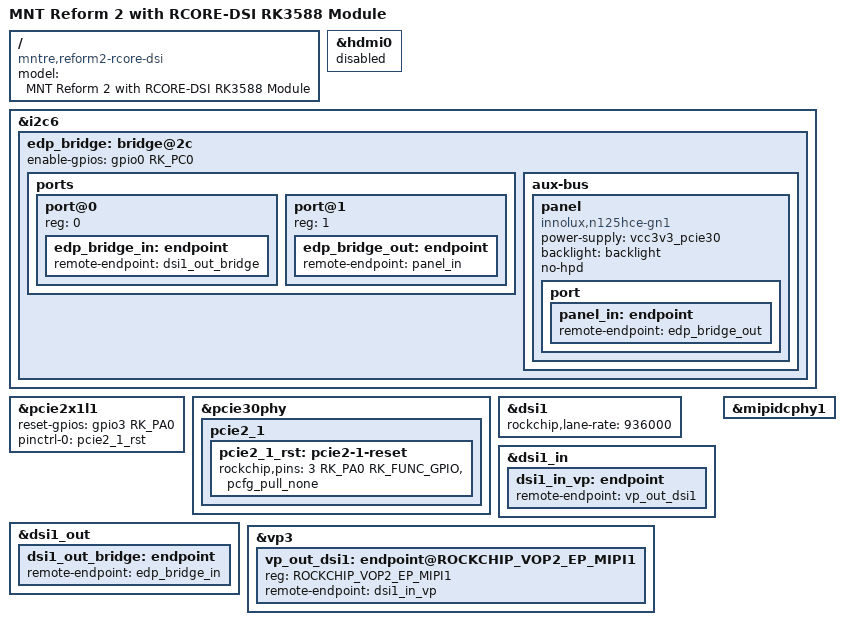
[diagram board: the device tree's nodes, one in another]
// SPDX-License-Identifier: (GPL-2.0+ OR MIT)
/*
 * Copyright (c) 2021 Rockchip Electronics Co., Ltd.
 * Copyright (c) 2024 MNT Research GmbH
 *
 */

/dts-v1/;

#include "rk3588-mnt-reform2.dts"

/ {
	model = "MNT Reform 2 with RCORE-DSI RK3588 Module";
	compatible = "mntre,reform2-rcore-dsi", "firefly,icore-3588q", "rockchip,rk3588";
};

&hdmi0 {
	status = "disabled";
};

&i2c6 {
	edp_bridge: bridge@2c {
		enable-gpios = <&gpio0 RK_PC0 GPIO_ACTIVE_HIGH>;
		status = "okay";

		ports {
			#address-cells = <1>;
			#size-cells = <0>;

			port@0 {
				reg = <0>;

				edp_bridge_in: endpoint {
					remote-endpoint = <&dsi1_out_bridge>;
				};
			};

			port@1 {
				reg = <1>;

				edp_bridge_out: endpoint {
					remote-endpoint = <&panel_in>;
				};
			};
		};

		aux-bus {
			panel: panel {
				compatible = "innolux,n125hce-gn1";
				power-supply = <&vcc3v3_pcie30>;
				backlight = <&backlight>;
				no-hpd;

				port {
					panel_in: endpoint {
						remote-endpoint = <&edp_bridge_out>;
					};
				};
			};
		};
	};
};

/* only for wifi/bt connector on RCORE R-2 */
&pcie2x1l1 {
	reset-gpios = <&gpio3 RK_PA0 GPIO_ACTIVE_HIGH>;
	pinctrl-names = "default";
	pinctrl-0 = <&pcie2_1_rst>;
	status = "okay";
};

&pcie30phy {
	pcie2_1 {
		pcie2_1_rst: pcie2-1-reset {
			rockchip,pins = <3 RK_PA0 RK_FUNC_GPIO &pcfg_pull_none>;
		};
	};
};

&dsi1 {
	rockchip,lane-rate = <936000>;
	status = "okay";
};

&dsi1_in {
	dsi1_in_vp: endpoint {
		remote-endpoint = <&vp_out_dsi1>;
	};
};

&dsi1_out {
	dsi1_out_bridge: endpoint {
		remote-endpoint = <&edp_bridge_in>;
	};
};

&mipidcphy1 {
	status = "okay";
};

&vp3 {
	vp_out_dsi1: endpoint@ROCKCHIP_VOP2_EP_MIPI1 {
		reg = <ROCKCHIP_VOP2_EP_MIPI1>;
		remote-endpoint = <&dsi1_in_vp>;
	};
};
